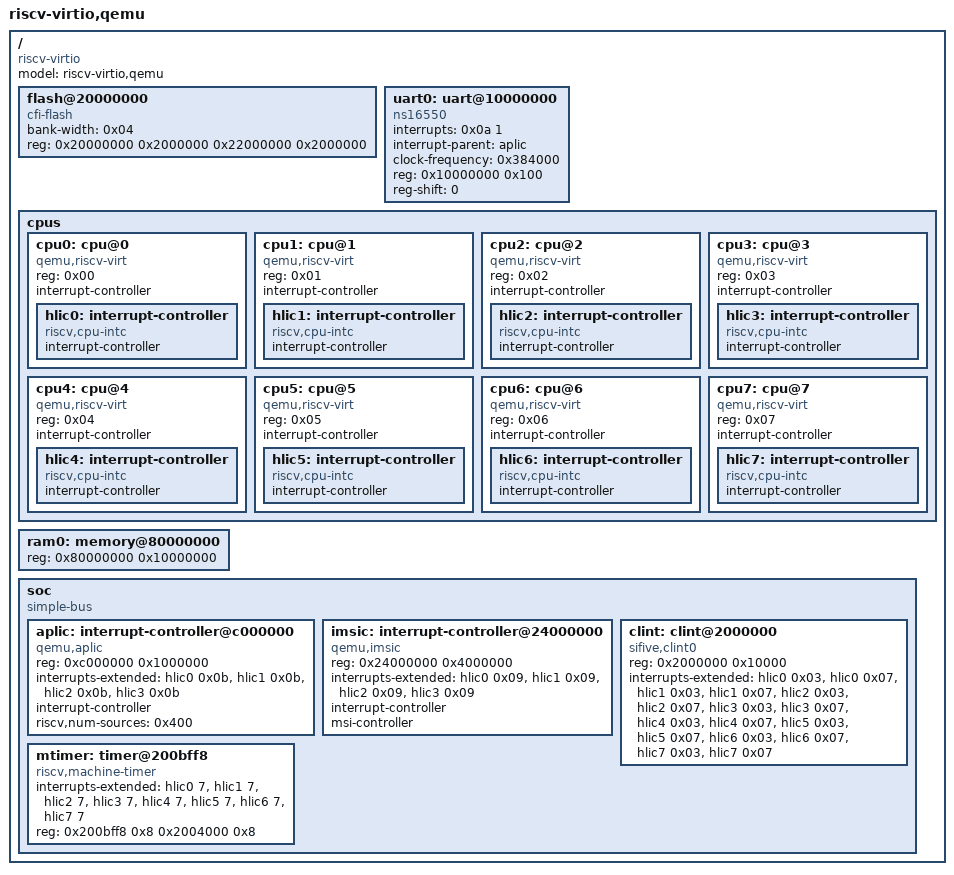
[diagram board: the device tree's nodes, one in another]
/*
 * Copyright (c) 2020 Cobham Gaisler AB
 *
 * SPDX-License-Identifier: Apache-2.0
 */

/*
 * This file is based on:
 *   qemu-system-riscv32 -machine virt,dumpdtb=virt.dtb -smp 8 -m 256
 *   dtc virt.dtb > virt.dtsi
 */

/dts-v1/;

/ {
	#address-cells = < 0x01 >;
	#size-cells = < 0x01 >;
	compatible = "riscv-virtio";
	model = "riscv-virtio,qemu";

	flash@20000000 {
		bank-width = < 0x04 >;
		reg = < 0x20000000 0x2000000 0x22000000 0x2000000 >;
		compatible = "cfi-flash";
	};

	uart0: uart@10000000 {
		interrupts = < 0x0a 1 >;
		interrupt-parent = < &aplic >;
		clock-frequency = < 0x384000 >;
		reg = < 0x10000000 0x100 >;
		compatible = "ns16550";
		reg-shift = < 0 >;
	};

	cpus {
		#address-cells = < 0x01 >;
		#size-cells = < 0x00 >;

		cpu0: cpu@0 {
			phandle = <0x0f>;
			device_type = "cpu";
			reg = < 0x00 >;
			status = "okay";
			compatible = "qemu,riscv-virt", "riscv";
			#interrupt-cells = <0x00>;
			interrupt-controller;

			hlic0: interrupt-controller {
				compatible = "riscv,cpu-intc";
				#address-cells = <0>;
				#interrupt-cells = < 0x01 >;
				interrupt-controller;
			};
		};

		cpu1: cpu@1 {
			phandle = <0x0d>;
			device_type = "cpu";
			reg = < 0x01 >;
			status = "okay";
			compatible = "qemu,riscv-virt", "riscv";
			#interrupt-cells = <0x00>;
			interrupt-controller;

			hlic1: interrupt-controller {
				compatible = "riscv,cpu-intc";
				#address-cells = <0>;
				#interrupt-cells = < 0x01 >;
				interrupt-controller;
			};
		};

		cpu2: cpu@2 {
			phandle = <0x0b>;
			device_type = "cpu";
			reg = < 0x02 >;
			status = "okay";
			compatible = "qemu,riscv-virt", "riscv";
			#interrupt-cells = <0x00>;
			interrupt-controller;

			hlic2: interrupt-controller {
				compatible = "riscv,cpu-intc";
				#address-cells = <0>;
				#interrupt-cells = < 0x01 >;
				interrupt-controller;
			};
		};

		cpu3: cpu@3 {
			phandle = <0x09>;
			device_type = "cpu";
			reg = < 0x03 >;
			status = "okay";
			compatible = "qemu,riscv-virt", "riscv";
			#interrupt-cells = <0x00>;
			interrupt-controller;

			hlic3: interrupt-controller {
				compatible = "riscv,cpu-intc";
				#address-cells = <0>;
				#interrupt-cells = < 0x01 >;
				interrupt-controller;
			};
		};

		cpu4: cpu@4 {
			phandle = <0x07>;
			device_type = "cpu";
			reg = < 0x04 >;
			status = "okay";
			compatible = "qemu,riscv-virt", "riscv";
			#interrupt-cells = <0x00>;
			interrupt-controller;

			hlic4: interrupt-controller {
				compatible = "riscv,cpu-intc";
				#address-cells = <0>;
				#interrupt-cells = < 0x01 >;
				interrupt-controller;
			};
		};

		cpu5: cpu@5 {
			phandle = <0x05>;
			device_type = "cpu";
			reg = < 0x05 >;
			status = "okay";
			compatible = "qemu,riscv-virt", "riscv";
			#interrupt-cells = <0x00>;
			interrupt-controller;

			hlic5: interrupt-controller {
				compatible = "riscv,cpu-intc";
				#address-cells = <0>;
				#interrupt-cells = < 0x01 >;
				interrupt-controller;
			};
		};

		cpu6: cpu@6 {
			phandle = <0x03>;
			device_type = "cpu";
			reg = < 0x06 >;
			status = "okay";
			compatible = "qemu,riscv-virt", "riscv";
			#interrupt-cells = <0x00>;
			interrupt-controller;

			hlic6: interrupt-controller {
				compatible = "riscv,cpu-intc";
				#address-cells = <0>;
				#interrupt-cells = < 0x01 >;
				interrupt-controller;
			};
		};

		cpu7: cpu@7 {
			phandle = <0x01>;
			device_type = "cpu";
			reg = < 0x07 >;
			status = "okay";
			compatible = "qemu,riscv-virt", "riscv";
			#interrupt-cells = <0x00>;
			interrupt-controller;

			hlic7: interrupt-controller {
				compatible = "riscv,cpu-intc";
				#address-cells = <0>;
				#interrupt-cells = < 0x01 >;
				interrupt-controller;
			};
		};
	};

	ram0: memory@80000000 {
		device_type = "memory";
		reg = < 0x80000000 0x10000000 >;
	};

	soc {
		#address-cells = < 0x01 >;
		#size-cells = < 0x01 >;
		compatible = "simple-bus";
		ranges;

		aplic: interrupt-controller@c000000 {
			compatible = "qemu,aplic", "riscv,aplic";
			reg = <0xc000000 0x1000000>;
			interrupts-extended = <&hlic0 0x0b>, <&hlic1 0x0b>, <&hlic2 0x0b>, <&hlic3 0x0b>;
			interrupt-controller;
			#interrupt-cells = <0x02>;
			riscv,num-sources = <0x400>;
		};

		imsic: interrupt-controller@24000000 {
			compatible = "qemu,imsic", "riscv,imsic";
			reg = <0x24000000 0x4000000>;
			interrupts-extended = <&hlic0 0x09>, <&hlic1 0x09>, <&hlic2 0x09>, <&hlic3 0x09>;
			interrupt-controller;
			#interrupt-cells = <0x00>;
			msi-controller;
		};

		clint: clint@2000000 {
			compatible = "sifive,clint0";
			reg = <0x2000000 0x10000>;
			interrupts-extended = <&hlic0 0x03 &hlic0 0x07
					       &hlic1 0x03 &hlic1 0x07
					       &hlic2 0x03 &hlic2 0x07
					       &hlic3 0x03 &hlic3 0x07
					       &hlic4 0x03 &hlic4 0x07
					       &hlic5 0x03 &hlic5 0x07
					       &hlic6 0x03 &hlic6 0x07
					       &hlic7 0x03 &hlic7 0x07>;
		};

		mtimer: timer@200bff8 {
			compatible = "riscv,machine-timer";
			interrupts-extended = <&hlic0 7
						&hlic1 7
						&hlic2 7
						&hlic3 7
						&hlic4 7
						&hlic5 7
						&hlic6 7
						&hlic7 7>;
			reg = <0x200bff8 0x8 0x2004000 0x8>;
			reg-names = "mtime", "mtimecmp";
		};
	};
};
